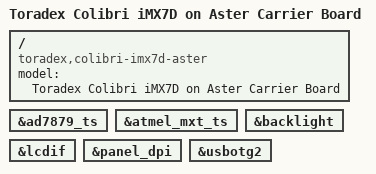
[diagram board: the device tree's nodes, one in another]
// SPDX-License-Identifier: GPL-2.0-or-later OR MIT
/*
 * Copyright 2017-2022 Toradex
 */

/dts-v1/;
#include "imx7d-colibri.dtsi"
#include "imx7-colibri-aster.dtsi"

/ {
	model = "Toradex Colibri iMX7D on Aster Carrier Board";
	compatible = "toradex,colibri-imx7d-aster",
		     "toradex,colibri-imx7d",
		     "fsl,imx7d";
};

&ad7879_ts {
	status = "okay";
};

&atmel_mxt_ts {
	status = "okay";
};

&backlight {
	status = "okay";
};

&lcdif {
	status = "okay";
};

&panel_dpi {
	status = "okay";
};

/* Colibri USBH */
&usbotg2 {
	status = "okay";
};
